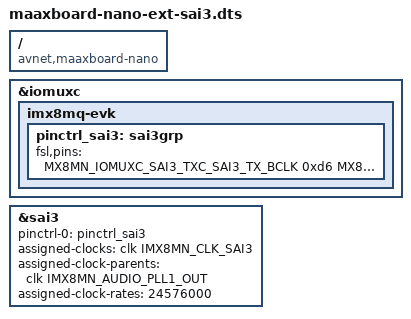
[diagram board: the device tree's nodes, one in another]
/*
 * Copyright 2021 AVNET
 *
 * This program is free software; you can redistribute it and/or
 * modify it under the terms of the GNU General Public License
 * as published by the Free Software Foundation; either version 2
 * of the License, or (at your option) any later version.
 *
 * This program is distributed in the hope that it will be useful,
 * but WITHOUT ANY WARRANTY; without even the implied warranty of
 * MERCHANTABILITY or FITNESS FOR A PARTICULAR PURPOSE.  See the
 * GNU General Public License for more details.
 */

/dts-v1/;
/plugin/;

#include <dt-bindings/clock/imx8mn-clock.h>
#include "../imx8mn-pinfunc.h"

/* 40-pin extended GPIO, expanded into SPI, I2C, PWM and other interfaces */

/ {
	compatible = "avnet,maaxboard-nano", "fsl,imx8mn";

	fragment@0 {
		target = <&iomuxc>;
		__overlay__ {
			imx8mq-evk {
				pinctrl_sai3: sai3grp {
					fsl,pins = <
						MX8MN_IOMUXC_SAI3_TXC_SAI3_TX_BCLK		0xd6 /* PIN 12,  GPIO5_IO0 */
						MX8MN_IOMUXC_SAI3_TXFS_SAI3_TX_SYNC		0xd6 /* PIN 35,  GPIO4_IO31 */
						MX8MN_IOMUXC_SAI3_RXD_SAI3_RX_DATA0		0xd6 /* PIN 38,  GPIO4_IO30 */
						MX8MN_IOMUXC_SAI3_TXD_SAI3_TX_DATA0		0xd6 /* PIN 40,  GPIO5_IO1 */
					>;
				};
			};
		};
	};

	fragment@1 {
		target = <&sai3>;
		__overlay__ {
			pinctrl-names = "default";
			pinctrl-0 = <&pinctrl_sai3>;
			assigned-clocks = <&clk IMX8MN_CLK_SAI3>;
			assigned-clock-parents = <&clk IMX8MN_AUDIO_PLL1_OUT>;
			assigned-clock-rates = <24576000>;
			status = "okay";
		};
	};
};
